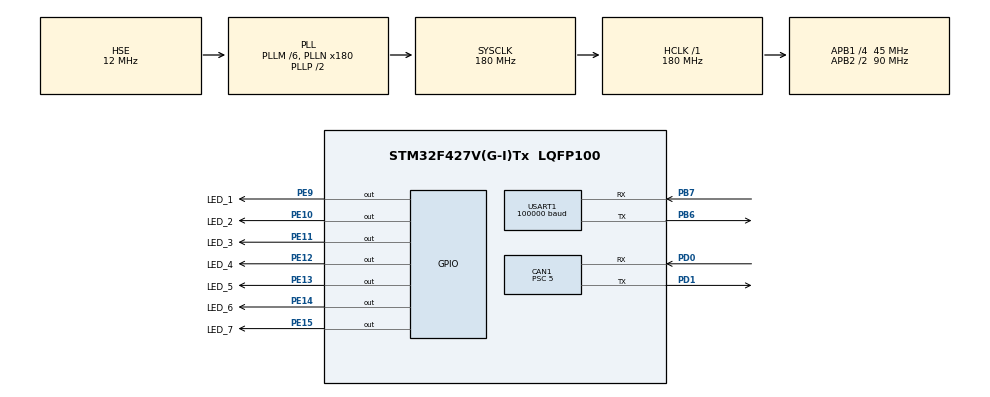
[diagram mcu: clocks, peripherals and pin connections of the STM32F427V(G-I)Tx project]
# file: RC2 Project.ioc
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CAN1.ABOM=ENABLE
CAN1.AWUM=ENABLE
CAN1.BS1=CAN_BS1_3TQ
CAN1.BS2=CAN_BS2_5TQ
CAN1.CalculateTimeQuantum=111.11111111111111
CAN1.Mode=CAN_MODE_NORMAL
CAN1.NART=DISABLE
CAN1.Prescaler=5
Dma.Request0=USART1_RX
Dma.USART1_RX.0.Direction=DMA_PERIPH_TO_MEMORY
Dma.USART1_RX.0.FIFOMode=DMA_FIFOMODE_DISABLE
Dma.USART1_RX.0.Instance=DMA2_Stream5
Dma.USART1_RX.0.MemDataAlignment=DMA_MDATAALIGN_BYTE
Dma.USART1_RX.0.MemInc=DMA_MINC_ENABLE
Dma.USART1_RX.0.Mode=DMA_CIRCULAR
Dma.USART1_RX.0.PeriphDataAlignment=DMA_PDATAALIGN_BYTE
Dma.USART1_RX.0.PeriphInc=DMA_PINC_DISABLE
Dma.USART1_RX.0.Priority=DMA_PRIORITY_MEDIUM
Mcu.Family=STM32F4
Mcu.Name=STM32F427V(G-I)Tx
Mcu.Package=LQFP100
NVIC.CAN1_RX0_IRQn=true\:1\:0\:true\:false\:true\:true\:true
NVIC.DMA2_Stream5_IRQn=true\:0\:0\:false\:false\:true\:false\:true
NVIC.PriorityGroup=NVIC_PRIORITYGROUP_4
NVIC.TIM6_DAC_IRQn=true\:0\:0\:false\:false\:true\:true\:true
NVIC.USART1_IRQn=true\:0\:0\:true\:false\:true\:true\:true
PA13.Mode=Serial_Wire
PA13.Signal=SYS_JTMS-SWDIO
PA14.Mode=Serial_Wire
PA14.Signal=SYS_JTCK-SWCLK
PB6.Mode=Asynchronous
PB6.Signal=USART1_TX
PB7.Mode=Asynchronous
PB7.Signal=USART1_RX
PD0.Mode=Master
PD0.Signal=CAN1_RX
PD1.Mode=Master
PD1.Signal=CAN1_TX
PE10.GPIO_Label=LED_2
PE10.Signal=GPIO_Output
PE11.GPIO_Label=LED_3
PE11.Signal=GPIO_Output
PE12.GPIO_Label=LED_4
PE12.Signal=GPIO_Output
PE13.GPIO_Label=LED_5
PE13.Signal=GPIO_Output
PE14.GPIO_Label=LED_6
PE14.Signal=GPIO_Output
PE15.GPIO_Label=LED_7
PE15.Signal=GPIO_Output
PE9.GPIO_Label=LED_1
PE9.Signal=GPIO_Output
PH0/OSC_IN.Mode=HSE-External-Oscillator
PH0/OSC_IN.Signal=RCC_OSC_IN
PH1/OSC_OUT.Mode=HSE-External-Oscillator
PH1/OSC_OUT.Signal=RCC_OSC_OUT
ProjectManager.HeapSize=0x200
ProjectManager.StackSize=0x400
ProjectManager.TargetToolchain=MDK-ARM V5
RCC.48MHZClocksFreq_Value=90000000
RCC.AHBFreq_Value=180000000
RCC.APB1CLKDivider=RCC_HCLK_DIV4
RCC.APB1Freq_Value=45000000
RCC.APB1TimFreq_Value=90000000
RCC.APB2CLKDivider=RCC_HCLK_DIV2
RCC.APB2Freq_Value=90000000
RCC.APB2TimFreq_Value=180000000
RCC.CortexFreq_Value=180000000
RCC.HCLKFreq_Value=180000000
RCC.HSE_VALUE=12000000
RCC.HSI_VALUE=16000000
RCC.LSE_VALUE=32768
RCC.PLLM=6
RCC.PLLN=180
RCC.PLLSourceVirtual=RCC_PLLSOURCE_HSE
RCC.SYSCLKFreq_VALUE=180000000
RCC.SYSCLKSource=RCC_SYSCLKSOURCE_PLLCLK
RCC.VCOOutputFreq_Value=360000000
TIM6.AutoReloadPreload=TIM_AUTORELOAD_PRELOAD_ENABLE
TIM6.Period=9999
TIM6.Prescaler=4499
TIM6.TIM_MasterOutputTrigger=TIM_TRGO_UPDATE
USART1.BaudRate=100000
USART1.Parity=PARITY_EVEN
USART1.VirtualMode=VM_ASYNC
VP_TIM6_VS_ClockSourceINT.Mode=Enable_Timer
board=custom

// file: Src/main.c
/* USER CODE BEGIN Header */
/**
  ******************************************************************************
  * @file           : main.c
  * @brief          : Main program body
  ******************************************************************************
  * @attention
  *
  * <h2><center>&copy; Copyright (c) 2020 STMicroelectronics.
  * All rights reserved.</center></h2>
  *
  * This software component is licensed by ST under BSD 3-Clause license,
  * the "License"; You may not use this file except in compliance with the
  * License. You may obtain a copy of the License at:
  *                        opensource.org/licenses/BSD-3-Clause
  *
  ******************************************************************************
  */
/* USER CODE END Header */

#include "main.h"
#include "can.h"
#include "dma.h"
#include "tim.h"
#include "usart.h"
#include "gpio.h"

/* USER CODE BEGIN Includes */
#include "Devices_DR16.h"
#include "Devices_Analysis.h"

/* USER CODE END Includes */

void SystemClock_Config(void);

int main(void)
{

  /* MCU Configuration--------------------------------------------------------*/

  /* Reset of all peripherals, Initializes the Flash interface and the Systick. */
  HAL_Init();

  /* Configure the system clock */
  SystemClock_Config();

  /* Initialize all configured peripherals */
  MX_GPIO_Init();
  MX_DMA_Init();
  MX_USART1_UART_Init();
  MX_TIM6_Init();
  MX_CAN1_Init();
  /* USER CODE BEGIN 2 */
	/*DR16_USART1中断启动初始化*/
	DR16_USART1_IT_Init();
	/*电机_CAN1中断初始化*/
	RM_MOTOR_CAN1_IT_Init();
  /* USER CODE END 2 */

  /* Infinite loop */
  while (1)
  {

    /* USER CODE BEGIN 3 */
//		CAN_CHECK = HAL_CAN_GetRxFifoFillLevel(&hcan1,CAN_RX_FIFO0);
  }
  /* USER CODE END 3 */
}

void SystemClock_Config(void)
{
  RCC_OscInitTypeDef RCC_OscInitStruct = {0};
  RCC_ClkInitTypeDef RCC_ClkInitStruct = {0};

  /** Configure the main internal regulator output voltage
  */
  __HAL_RCC_PWR_CLK_ENABLE();
  __HAL_PWR_VOLTAGESCALING_CONFIG(PWR_REGULATOR_VOLTAGE_SCALE1);
  /** Initializes the CPU, AHB and APB busses clocks
  */
  RCC_OscInitStruct.OscillatorType = RCC_OSCILLATORTYPE_HSE;
  RCC_OscInitStruct.HSEState = RCC_HSE_ON;
  RCC_OscInitStruct.PLL.PLLState = RCC_PLL_ON;
  RCC_OscInitStruct.PLL.PLLSource = RCC_PLLSOURCE_HSE;
  RCC_OscInitStruct.PLL.PLLM = 6;
  RCC_OscInitStruct.PLL.PLLN = 180;
  RCC_OscInitStruct.PLL.PLLP = RCC_PLLP_DIV2;
  RCC_OscInitStruct.PLL.PLLQ = 4;
  if (HAL_RCC_OscConfig(&RCC_OscInitStruct) != HAL_OK)
  {
    Error_Handler();
  }
  /** Activate the Over-Drive mode
  */
  if (HAL_PWREx_EnableOverDrive() != HAL_OK)
  {
    Error_Handler();
  }
  /** Initializes the CPU, AHB and APB busses clocks
  */
  RCC_ClkInitStruct.ClockType = RCC_CLOCKTYPE_HCLK|RCC_CLOCKTYPE_SYSCLK
                              |RCC_CLOCKTYPE_PCLK1|RCC_CLOCKTYPE_PCLK2;
  RCC_ClkInitStruct.SYSCLKSource = RCC_SYSCLKSOURCE_PLLCLK;
  RCC_ClkInitStruct.AHBCLKDivider = RCC_SYSCLK_DIV1;
  RCC_ClkInitStruct.APB1CLKDivider = RCC_HCLK_DIV4;
  RCC_ClkInitStruct.APB2CLKDivider = RCC_HCLK_DIV2;

  if (HAL_RCC_ClockConfig(&RCC_ClkInitStruct, FLASH_LATENCY_5) != HAL_OK)
  {
    Error_Handler();
  }
}

void Error_Handler(void)
{
}

/************************ (C) COPYRIGHT STMicroelectronics *****END OF FILE****/
